# STM32WL3xx register map
File version: 1.0
Registers are 32-bit, read-write, reset 0x0 unless marked. A register's access mark holds for its fields unless they carry their own. Offsets are from the block's base; [hi:lo] are bit positions; {n}, {i} and the like mark numbered series.

## RTC — Real-time clock (RTC)
Base 0x40004000
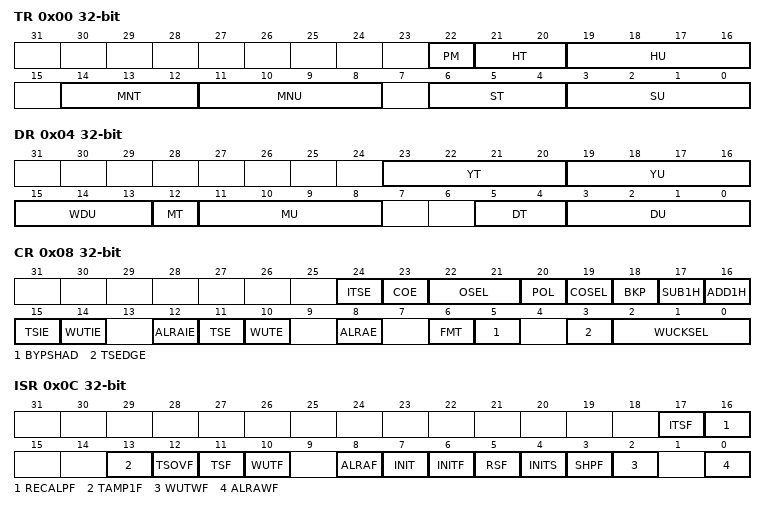
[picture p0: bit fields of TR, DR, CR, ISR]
0x00 TR — (@ 0x00000000) Time register
  [22] PM
    0=AM_OR_24 (AM or 24-hour format); 1=PM
  [21:20] HT
  [19:16] HU
  [14:12] MNT
  [11:8] MNU
  [6:4] ST
  [3:0] SU
0x04 DR — (@ 0x00000004) Date register
  [23:20] YT, [19:16] YU, [15:13] WDU, [12] MT, [11:8] MU, [5:4] DT, [3:0] DU
0x08 CR — (@ 0x00000008) Control register
  [24] ITSE
  [23] COE
  [22:21] OSEL
    0=DISABLE (Output disabled); 1=ALMA (Alarm A output enabled); 2=ALMB (Alarm B output enabled); 3=WAKEUP (Wakeup output enabled)
  [20] POL
    0=HIGH (Pin is high when ALRAF/ALRBF/WUTF is asserted (depending on OSEL)); 1=LOW (Pin is low when ALRAF/ALRBF/WUTF is asserted (depending on OSEL))
  [19] COSEL
  [18] BKP
  [17] SUB1H
  [16] ADD1H
  [15] TSIE
  [14] WUTIE
  [12] ALRAIE
  [11] TSE
  [10] WUTE
  [8] ALRAE
  [6] FMT
    0=HOURFORMAT_24HOUR (24 hour/day format); 1=AMPM (AM/PM hour format)
  [5] BYPSHAD
  [3] TSEDGE
    0=RISING (RTC_TS input rising edge generates a time-stamp event); 1=FALLING (RTC_TS input falling edge generates a time-stamp event)
  [2:0] WUCKSEL
    0=DIV_16 (RTC/16 clock is selected); 1=DIV_8 (RTC/8 clock is selected); 2=DIV_4 (RTC/4 clock is selected); 3=DIV_2 (RTC/2 clock is selected); 4=CKSPRE (ck_spre (usually 1 Hz) clock is selected); 6=CKSPRE_WUT (ck_spre (usually 1 Hz) clock is selected and 2exp16 is added to the WUT counter value)
0x0C ISR — (@ 0x0000000C) Initialization and status register
  [17] ITSF, [16] RECALPF, [13] TAMP1F, [12] TSOVF, [11] TSF, [10] WUTF, [8] ALRAF, [7] INIT, [6] INITF, [5] RSF, [4] INITS, [3] SHPF, [2] WUTWF, [0] ALRAWF
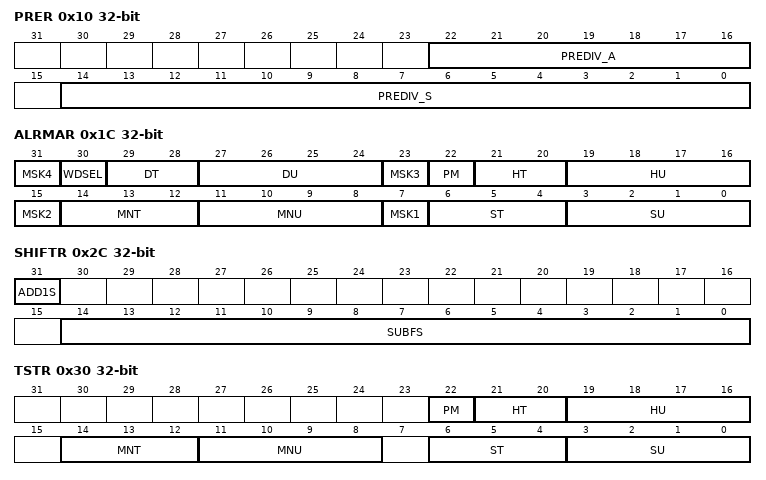
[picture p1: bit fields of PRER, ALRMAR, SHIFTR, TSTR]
0x10 PRER — (@ 0x00000010) Prescaler register
  [22:16] PREDIV_A, [14:0] PREDIV_S
0x14 WUTR — (@ 0x00000014) Wakeup timer register
  [15:0] WUT
0x1C ALRMAR — (@ 0x0000001C) Alarm A register
  [8n-1] MSK{n} (n=1..4)
  [30] WDSEL
  [29:28] DT
  [27:24] DU
  [22] PM
    0=AM (AM or 24-hour format); 1=PM
  [21:20] HT
  [19:16] HU
  [14:12] MNT
  [11:8] MNU
  [6:4] ST
  [3:0] SU
0x24 WPR — (@ 0x00000024) Write protection register
  [7:0] KEY
0x28 SSR — (@ 0x00000028) Sub second register
  [15:0] SS
0x2C SHIFTR — (@ 0x0000002C) Shift control register
  [31] ADD1S, [14:0] SUBFS
0x30 TSTR — (@ 0x00000030) Timestamp time register
  [22] PM
    0=AM (AM or 24-hour format); 1=PM
  [21:20] HT
  [19:16] HU
  [14:12] MNT
  [11:8] MNU
  [6:4] ST
  [3:0] SU
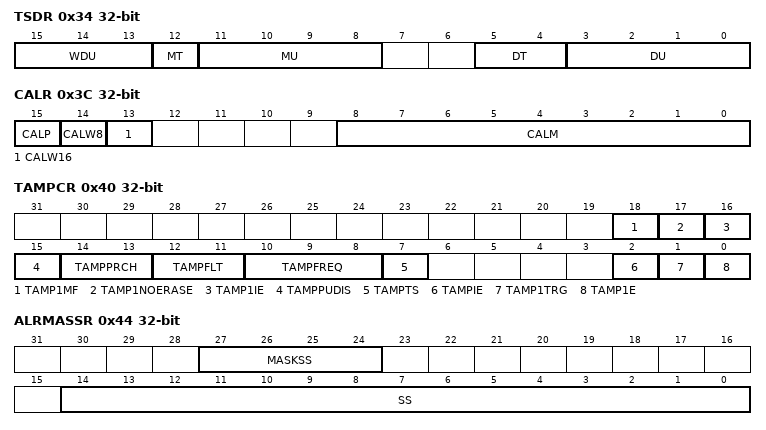
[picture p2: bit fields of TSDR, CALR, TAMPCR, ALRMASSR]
0x34 TSDR — (@ 0x00000034) Timestamp date register
  [15:13] WDU, [12] MT, [11:8] MU, [5:4] DT, [3:0] DU
0x38 TSSSR — (@ 0x00000038) Timestamp sub second register
  [15:0] SS
0x3C CALR — (@ 0x0000003C) Calibration register
  [15] CALP
    0=NONE (No RTCCLK pulses are added); 1=SET (One RTCCLK pulse is effectively inserted every 2exp11 pulses (frequency increased by 488.5 ppm))
  [14] CALW8
  [13] CALW16
  [8:0] CALM
0x40 TAMPCR — (@ 0x00000040) Tamper configuration register
  [18] TAMP1MF
  [17] TAMP1NOERASE
  [16] TAMP1IE
  [15] TAMPPUDIS
  [14:13] TAMPPRCH
    0=DURATION_1RTCCLK (Tamper pins are pre-charged before sampling during 1 RTCCLK cycle); 1=DURATION_2RTCCLK (Tamper pins are pre-charged before sampling during 2 RTCCLK cycles); 2=DURATION_4RTCCLK (Tamper pins are pre-charged before sampling during 4 RTCCLK cycles); 3=DURATION_8RTCCLK (Tamper pins are pre-charged before sampling during 8 RTCCLK cycles)
  [12:11] TAMPFLT
    0=DISABLE (Tamper filter is disabled); 1=FILTER_2SAMPLE (Tamper is activated after 2 consecutive samples at the active level); 2=FILTER_4SAMPLE (Tamper is activated after 4 consecutive samples at the active level); 3=FILTER_8SAMPLE (Tamper is activated after 8 consecutive samples at the active level.)
  [10:8] TAMPFREQ
    0=SAMPLFREQDIV_32768 (Each of the tamper inputs are sampled with a frequency = RTCCLK / 32768); 1=SAMPLFREQDIV_16384 (Each of the tamper inputs are sampled with a frequency = RTCCLK / 16384); 2=SAMPLFREQDIV_8192 (Each of the tamper inputs are sampled with a frequency = RTCCLK / 8192); 3=SAMPLFREQDIV_4096 (Each of the tamper inputs are sampled with a frequency = RTCCLK / 4096); 4=SAMPLFREQDIV_2048 (Each of the tamper inputs are sampled with a frequency = RTCCLK / 2048); 5=SAMPLFREQDIV_1024 (Each of the tamper inputs are sampled with a frequency = RTCCLK / 1024); 6=SAMPLFREQDIV_512 (Each of the tamper inputs are sampled with a frequency = RTCCLK / 512); 7=SAMPLFREQDIV_256 (Each of the tamper inputs are sampled with a frequency = RTCCLK / 256)
  [7] TAMPTS
  [2] TAMPIE
  [1] TAMP1TRG
  [0] TAMP1E
0x44 ALRMASSR — (@ 0x00000044) Alarm A sub second register
  [27:24] MASKSS, [14:0] SS
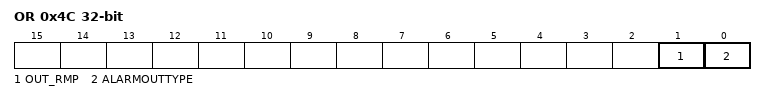
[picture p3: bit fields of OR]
0x4C OR — (@ 0x0000004C) Option register
  [1] OUT_RMP
  [0] ALARMOUTTYPE
    0=OPENDRAIN (RTC_ALARM, when mapped on PC13, is open-drain output); 1=PUSHPULL (RTC_ALARM, when mapped on PC13, is push-pull output)
0x50 BKP0R — (@ 0x00000050) Backup register 0
  [31:0] BKP
0x54 BKP1R — (@ 0x00000054) Backup register 1
  [31:0] BKP
